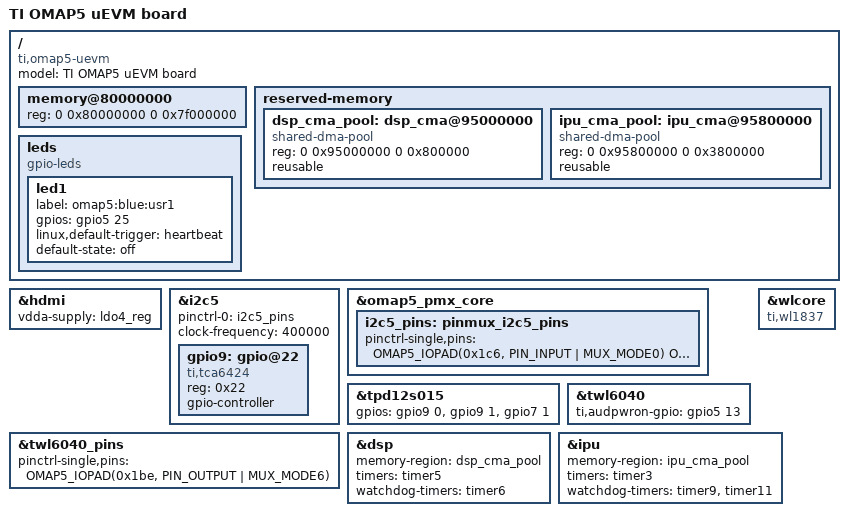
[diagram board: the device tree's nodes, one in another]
/*
 * Copyright (C) 2013 Texas Instruments Incorporated - http://www.ti.com/
 *
 * This program is free software; you can redistribute it and/or modify
 * it under the terms of the GNU General Public License version 2 as
 * published by the Free Software Foundation.
 */
/dts-v1/;

#include "omap5-board-common.dtsi"

/ {
	model = "TI OMAP5 uEVM board";
	compatible = "ti,omap5-uevm", "ti,omap5";

	memory@80000000 {
		device_type = "memory";
		reg = <0 0x80000000 0 0x7f000000>; /* 2032 MB */
	};

	reserved-memory {
		#address-cells = <2>;
		#size-cells = <2>;
		ranges;

		dsp_cma_pool: dsp_cma@95000000 {
			compatible = "shared-dma-pool";
			reg = <0 0x95000000 0 0x800000>;
			reusable;
			status = "okay";
		};

		ipu_cma_pool: ipu_cma@95800000 {
			compatible = "shared-dma-pool";
			reg = <0 0x95800000 0 0x3800000>;
			reusable;
			status = "okay";
		};
	};

	leds {
		compatible = "gpio-leds";
		led1 {
			label = "omap5:blue:usr1";
			gpios = <&gpio5 25 GPIO_ACTIVE_HIGH>; /* gpio5_153 D1 LED */
			linux,default-trigger = "heartbeat";
			default-state = "off";
		};
	};
};

&hdmi {
	vdda-supply = <&ldo4_reg>;
};

&i2c5 {
	pinctrl-names = "default";
	pinctrl-0 = <&i2c5_pins>;

	clock-frequency = <400000>;

	gpio9: gpio@22 {
		compatible = "ti,tca6424";
		reg = <0x22>;
		gpio-controller;
		#gpio-cells = <2>;
	};
};

&omap5_pmx_core {
	i2c5_pins: pinmux_i2c5_pins {
		pinctrl-single,pins = <
			OMAP5_IOPAD(0x1c6, PIN_INPUT | MUX_MODE0)		/* i2c5_scl */
			OMAP5_IOPAD(0x1c8, PIN_INPUT | MUX_MODE0)		/* i2c5_sda */
		>;
	};
};

&tpd12s015 {
	gpios = <&gpio9 0 GPIO_ACTIVE_HIGH>,	/* TCA6424A P01, CT CP HPD */
		<&gpio9 1 GPIO_ACTIVE_HIGH>,	/* TCA6424A P00, LS OE */
		<&gpio7 1 GPIO_ACTIVE_HIGH>;	/* GPIO 193, HPD */
};

&twl6040 {
	ti,audpwron-gpio = <&gpio5 13 GPIO_ACTIVE_HIGH>;  /* gpio line 141 */
};

&twl6040_pins {
	pinctrl-single,pins = <
		OMAP5_IOPAD(0x1be, PIN_OUTPUT | MUX_MODE6)	/* mcspi1_somi.gpio5_141 */
	>;
};

&wlcore {
	compatible = "ti,wl1837";
};

&dsp {
	status = "okay";
	memory-region = <&dsp_cma_pool>;
	timers = <&timer5>;
	watchdog-timers = <&timer6>;
};

&ipu {
	status = "okay";
	memory-region = <&ipu_cma_pool>;
	timers = <&timer3>;
	watchdog-timers = <&timer9>, <&timer11>;
};
